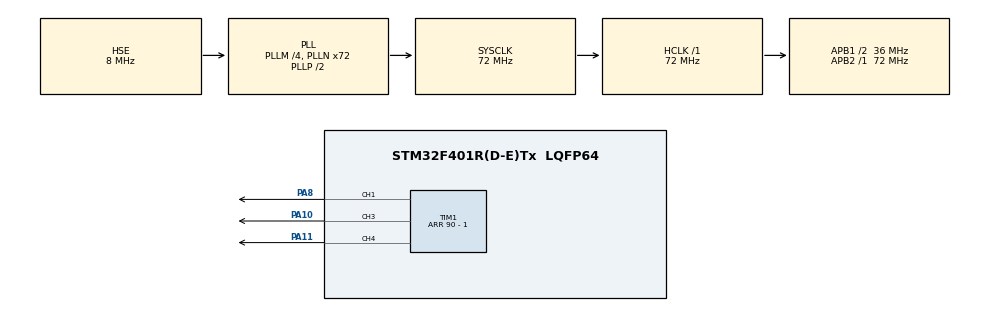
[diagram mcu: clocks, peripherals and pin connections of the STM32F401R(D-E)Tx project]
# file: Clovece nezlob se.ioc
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Dma.Request0=TIM1_CH1
Dma.Request1=TIM1_CH3
Dma.Request2=TIM1_CH4/TRIG/COM
Dma.TIM1_CH1.0.Direction=DMA_MEMORY_TO_PERIPH
Dma.TIM1_CH1.0.FIFOMode=DMA_FIFOMODE_DISABLE
Dma.TIM1_CH1.0.Instance=DMA2_Stream1
Dma.TIM1_CH1.0.MemDataAlignment=DMA_MDATAALIGN_HALFWORD
Dma.TIM1_CH1.0.MemInc=DMA_MINC_ENABLE
Dma.TIM1_CH1.0.Mode=DMA_NORMAL
Dma.TIM1_CH1.0.PeriphDataAlignment=DMA_PDATAALIGN_HALFWORD
Dma.TIM1_CH1.0.PeriphInc=DMA_PINC_DISABLE
Dma.TIM1_CH1.0.Priority=DMA_PRIORITY_LOW
Dma.TIM1_CH3.1.Direction=DMA_MEMORY_TO_PERIPH
Dma.TIM1_CH3.1.FIFOMode=DMA_FIFOMODE_DISABLE
Dma.TIM1_CH3.1.Instance=DMA2_Stream6
Dma.TIM1_CH3.1.MemDataAlignment=DMA_MDATAALIGN_HALFWORD
Dma.TIM1_CH3.1.MemInc=DMA_MINC_ENABLE
Dma.TIM1_CH3.1.Mode=DMA_NORMAL
Dma.TIM1_CH3.1.PeriphDataAlignment=DMA_PDATAALIGN_HALFWORD
Dma.TIM1_CH3.1.PeriphInc=DMA_PINC_DISABLE
Dma.TIM1_CH3.1.Priority=DMA_PRIORITY_LOW
Dma.TIM1_CH4/TRIG/COM.2.Direction=DMA_MEMORY_TO_PERIPH
Dma.TIM1_CH4/TRIG/COM.2.FIFOMode=DMA_FIFOMODE_DISABLE
Dma.TIM1_CH4/TRIG/COM.2.Instance=DMA2_Stream4
Dma.TIM1_CH4/TRIG/COM.2.MemDataAlignment=DMA_MDATAALIGN_HALFWORD
Dma.TIM1_CH4/TRIG/COM.2.MemInc=DMA_MINC_ENABLE
Dma.TIM1_CH4/TRIG/COM.2.Mode=DMA_NORMAL
Dma.TIM1_CH4/TRIG/COM.2.PeriphDataAlignment=DMA_PDATAALIGN_HALFWORD
Dma.TIM1_CH4/TRIG/COM.2.PeriphInc=DMA_PINC_DISABLE
Dma.TIM1_CH4/TRIG/COM.2.Priority=DMA_PRIORITY_LOW
Mcu.Family=STM32F4
Mcu.Name=STM32F401R(D-E)Tx
Mcu.Package=LQFP64
NVIC.DMA2_Stream1_IRQn=true\:0\:0\:false\:false\:true\:false\:true\:true
NVIC.DMA2_Stream4_IRQn=true\:0\:0\:false\:false\:true\:false\:true\:true
NVIC.DMA2_Stream6_IRQn=true\:0\:0\:false\:false\:true\:false\:true\:true
NVIC.PriorityGroup=NVIC_PRIORITYGROUP_4
PA10.Signal=S_TIM1_CH3
PA11.Signal=S_TIM1_CH4
PA8.Signal=S_TIM1_CH1
PH0\ -\ OSC_IN.Mode=HSE-External-Clock-Source
PH0\ -\ OSC_IN.Signal=RCC_OSC_IN
PH1\ -\ OSC_OUT.Mode=HSE-External-Clock-Source
PH1\ -\ OSC_OUT.Signal=RCC_OSC_OUT
ProjectManager.HeapSize=0x200
ProjectManager.StackSize=0x400
ProjectManager.TargetToolchain=STM32CubeIDE
RCC.48MHZClocksFreq_Value=36000000
RCC.AHBFreq_Value=72000000
RCC.APB1CLKDivider=RCC_HCLK_DIV2
RCC.APB1Freq_Value=36000000
RCC.APB1TimFreq_Value=72000000
RCC.APB2Freq_Value=72000000
RCC.APB2TimFreq_Value=72000000
RCC.CortexFreq_Value=72000000
RCC.HCLKFreq_Value=72000000
RCC.HSE_VALUE=8000000
RCC.HSI_VALUE=16000000
RCC.LSE_VALUE=32768
RCC.PLLM=4
RCC.PLLN=72
RCC.PLLSourceVirtual=RCC_PLLSOURCE_HSE
RCC.SYSCLKFreq_VALUE=72000000
RCC.SYSCLKSource=RCC_SYSCLKSOURCE_PLLCLK
RCC.VCOOutputFreq_Value=144000000
SH.S_TIM1_CH1.0=TIM1_CH1,PWM Generation1 CH1
SH.S_TIM1_CH3.0=TIM1_CH3,PWM Generation3 CH3
SH.S_TIM1_CH4.0=TIM1_CH4,PWM Generation4 CH4
TIM1.Channel-PWM\ Generation1\ CH1=TIM_CHANNEL_1
TIM1.Channel-PWM\ Generation3\ CH3=TIM_CHANNEL_3
TIM1.Channel-PWM\ Generation4\ CH4=TIM_CHANNEL_4
TIM1.Period=90 - 1
VP_TIM1_VS_ClockSourceINT.Mode=Internal
board=custom

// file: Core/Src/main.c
/* USER CODE BEGIN Header */
/**
  ******************************************************************************
  * @file           : main.c
  * @brief          : Main program body
  ******************************************************************************
  * @attention
  *
  * Copyright (c) 2024 STMicroelectronics.
  * All rights reserved.
  *
  * This software is licensed under terms that can be found in the LICENSE file
  * in the root directory of this software component.
  * If no LICENSE file comes with this software, it is provided AS-IS.
  *
  ******************************************************************************
  */
/* USER CODE END Header */
#include "main.h"

/* USER CODE BEGIN Includes */
#include "ws2812b.h"
#include "clovece_nezlob_se.h"
/* USER CODE END Includes */

TIM_HandleTypeDef htim1;
DMA_HandleTypeDef hdma_tim1_ch1;
DMA_HandleTypeDef hdma_tim1_ch3;
DMA_HandleTypeDef hdma_tim1_ch4_trig_com;

void SystemClock_Config(void);
static void MX_GPIO_Init(void);
static void MX_DMA_Init(void);
static void MX_TIM1_Init(void);

/* USER CODE BEGIN 0 */
void test_game(void);
void indivudual_bright(void);
/* USER CODE END 0 */

int main(void)
{

  /* MCU Configuration--------------------------------------------------------*/

  /* Reset of all peripherals, Initializes the Flash interface and the Systick. */
  HAL_Init();

  /* Conpawn the system clock */
  SystemClock_Config();

  /* Initialize all conpawnd peripherals */
  MX_GPIO_Init();
  MX_DMA_Init();
  MX_TIM1_Init();

  /* Infinite loop */
  /* USER CODE BEGIN WHILE */
  init_brightness();
  init_board(4);		//Bug - when more pawn of the same color are on the same postion and a pawn is meant to be kicked out all the pawns of the same color get kicked out instead of just one
  	  	  	  	  	  	//Add: animation effect when pawns of the same colora are oń the same position
  	  	  	  	  	  	//Add: cannot kickout when on the player x start postion, at the start of the game yiu can roll 3 times if you dont roll a 6
  // Test if all the pawns can reach the end
  /*
  for(int player = 1; player < 5; player++){
	  for(int pawn = 0; pawn < 4; pawn++){
		  select_pawn(player, pawn);
		  move_pawn(player, 6);
		  move_pawn(player, 50);
	  }
  }
  */
  test_game();

/*
  select_pawn(2, 0);
  move_pawn(2, 6);

  select_pawn(2, 1);
  move_pawn(2, 6);

  select_pawn(2, 2);
  move_pawn(2, 6);

  select_pawn(1, 0);
  move_pawn(1, 6);

  select_pawn(1, 1);
  move_pawn(1, 6);

  select_pawn(4, 0);
  move_pawn(4, 6);

  check_for_overlap();
  //roll_dice(1, 6);
  */
  check_for_overlap();

  while (1)
  {
	  overlap_animation();
	  selected_pawn_animation(4);
    /* USER CODE END WHILE */

  }
}

void SystemClock_Config(void)
{
  RCC_OscInitTypeDef RCC_OscInitStruct = {0};
  RCC_ClkInitTypeDef RCC_ClkInitStruct = {0};

  /** Conpawn the main internal regulator output voltage
  */
  __HAL_RCC_PWR_CLK_ENABLE();
  __HAL_PWR_VOLTAGESCALING_CONFIG(PWR_REGULATOR_VOLTAGE_SCALE2);

  /** Initializes the RCC Oscillators according to the specified parameters
  * in the RCC_OscInitTypeDef structure.
  */
  RCC_OscInitStruct.OscillatorType = RCC_OSCILLATORTYPE_HSE;
  RCC_OscInitStruct.HSEState = RCC_HSE_BYPASS;
  RCC_OscInitStruct.PLL.PLLState = RCC_PLL_ON;
  RCC_OscInitStruct.PLL.PLLSource = RCC_PLLSOURCE_HSE;
  RCC_OscInitStruct.PLL.PLLM = 4;
  RCC_OscInitStruct.PLL.PLLN = 72;
  RCC_OscInitStruct.PLL.PLLP = RCC_PLLP_DIV2;
  RCC_OscInitStruct.PLL.PLLQ = 4;
  if (HAL_RCC_OscConfig(&RCC_OscInitStruct) != HAL_OK)
  {
    Error_Handler();
  }

  /** Initializes the CPU, AHB and APB buses clocks
  */
  RCC_ClkInitStruct.ClockType = RCC_CLOCKTYPE_HCLK|RCC_CLOCKTYPE_SYSCLK
                              |RCC_CLOCKTYPE_PCLK1|RCC_CLOCKTYPE_PCLK2;
  RCC_ClkInitStruct.SYSCLKSource = RCC_SYSCLKSOURCE_PLLCLK;
  RCC_ClkInitStruct.AHBCLKDivider = RCC_SYSCLK_DIV1;
  RCC_ClkInitStruct.APB1CLKDivider = RCC_HCLK_DIV2;
  RCC_ClkInitStruct.APB2CLKDivider = RCC_HCLK_DIV1;

  if (HAL_RCC_ClockConfig(&RCC_ClkInitStruct, FLASH_LATENCY_2) != HAL_OK)
  {
    Error_Handler();
  }
}

static void MX_TIM1_Init(void)
{

  TIM_ClockConfigTypeDef sClockSourceConfig = {0};
  TIM_MasterConfigTypeDef sMasterConfig = {0};
  TIM_OC_InitTypeDef sConfigOC = {0};
  TIM_BreakDeadTimeConfigTypeDef sBreakDeadTimeConfig = {0};

  htim1.Instance = TIM1;
  htim1.Init.Prescaler = 0;
  htim1.Init.CounterMode = TIM_COUNTERMODE_UP;
  htim1.Init.Period = 90 - 1;
  htim1.Init.ClockDivision = TIM_CLOCKDIVISION_DIV1;
  htim1.Init.RepetitionCounter = 0;
  htim1.Init.AutoReloadPreload = TIM_AUTORELOAD_PRELOAD_DISABLE;
  if (HAL_TIM_Base_Init(&htim1) != HAL_OK)
  {
    Error_Handler();
  }
  sClockSourceConfig.ClockSource = TIM_CLOCKSOURCE_INTERNAL;
  if (HAL_TIM_ConfigClockSource(&htim1, &sClockSourceConfig) != HAL_OK)
  {
    Error_Handler();
  }
  if (HAL_TIM_PWM_Init(&htim1) != HAL_OK)
  {
    Error_Handler();
  }
  sMasterConfig.MasterOutputTrigger = TIM_TRGO_RESET;
  sMasterConfig.MasterSlaveMode = TIM_MASTERSLAVEMODE_DISABLE;
  if (HAL_TIMEx_MasterConfigSynchronization(&htim1, &sMasterConfig) != HAL_OK)
  {
    Error_Handler();
  }
  sConfigOC.OCMode = TIM_OCMODE_PWM1;
  sConfigOC.Pulse = 0;
  sConfigOC.OCPolarity = TIM_OCPOLARITY_HIGH;
  sConfigOC.OCNPolarity = TIM_OCNPOLARITY_HIGH;
  sConfigOC.OCFastMode = TIM_OCFAST_DISABLE;
  sConfigOC.OCIdleState = TIM_OCIDLESTATE_RESET;
  sConfigOC.OCNIdleState = TIM_OCNIDLESTATE_RESET;
  if (HAL_TIM_PWM_ConfigChannel(&htim1, &sConfigOC, TIM_CHANNEL_1) != HAL_OK)
  {
    Error_Handler();
  }
  if (HAL_TIM_PWM_ConfigChannel(&htim1, &sConfigOC, TIM_CHANNEL_3) != HAL_OK)
  {
    Error_Handler();
  }
  if (HAL_TIM_PWM_ConfigChannel(&htim1, &sConfigOC, TIM_CHANNEL_4) != HAL_OK)
  {
    Error_Handler();
  }
  sBreakDeadTimeConfig.OffStateRunMode = TIM_OSSR_DISABLE;
  sBreakDeadTimeConfig.OffStateIDLEMode = TIM_OSSI_DISABLE;
  sBreakDeadTimeConfig.LockLevel = TIM_LOCKLEVEL_OFF;
  sBreakDeadTimeConfig.DeadTime = 0;
  sBreakDeadTimeConfig.BreakState = TIM_BREAK_DISABLE;
  sBreakDeadTimeConfig.BreakPolarity = TIM_BREAKPOLARITY_HIGH;
  sBreakDeadTimeConfig.AutomaticOutput = TIM_AUTOMATICOUTPUT_DISABLE;
  if (HAL_TIMEx_ConfigBreakDeadTime(&htim1, &sBreakDeadTimeConfig) != HAL_OK)
  {
    Error_Handler();
  }
  HAL_TIM_MspPostInit(&htim1);

}

static void MX_DMA_Init(void)
{

  /* DMA controller clock enable */
  __HAL_RCC_DMA2_CLK_ENABLE();

  /* DMA interrupt init */
  /* DMA2_Stream1_IRQn interrupt configuration */
  HAL_NVIC_SetPriority(DMA2_Stream1_IRQn, 0, 0);
  HAL_NVIC_EnableIRQ(DMA2_Stream1_IRQn);
  /* DMA2_Stream4_IRQn interrupt configuration */
  HAL_NVIC_SetPriority(DMA2_Stream4_IRQn, 0, 0);
  HAL_NVIC_EnableIRQ(DMA2_Stream4_IRQn);
  /* DMA2_Stream6_IRQn interrupt configuration */
  HAL_NVIC_SetPriority(DMA2_Stream6_IRQn, 0, 0);
  HAL_NVIC_EnableIRQ(DMA2_Stream6_IRQn);

}

static void MX_GPIO_Init(void)
{

  /* GPIO Ports Clock Enable */
  __HAL_RCC_GPIOH_CLK_ENABLE();
  __HAL_RCC_GPIOA_CLK_ENABLE();

}

/* USER CODE BEGIN 4 */
void test_game(void){
	  select_pawn(2, 1);
	  move_pawn(2, 6);

	  select_pawn(2, 3);
	  move_pawn(2, 6);

	  select_pawn(2, 2);
	  move_pawn(2, 6);

	  select_pawn(2, 0);
	  move_pawn(2, 6);

	  //move pawn from player 4
	  select_pawn(4, 0);
	  move_pawn(4, 6);

	  //move pawn on the board
	  select_pawn(2, 2);
	  move_pawn(2, 3);

	  select_pawn(2, 1);
	  move_pawn(2, 5);

	  select_pawn(2, 3);
	  move_pawn(2, 6);

	  select_pawn(2, 0);
	  move_pawn(2, 2);

	  select_pawn(4, 0);
	  move_pawn(4, 2);

	  // Sets the pawn to the start of the board
	  move_pawn(2, 40);

	  select_pawn(2, 1);
	  move_pawn(2, 40);

	  select_pawn(2, 2);
	  move_pawn(2, 40);

	  select_pawn(2, 3);
	  move_pawn(2, 40);

	  select_pawn(1, 2);
	  move_pawn(1, 2);

	  move_pawn(1, 6);
	  move_pawn(1, 40);

	  select_pawn(1, 3);
	  move_pawn(1, 6);
	  move_pawn(1, 6);

	  select_pawn(3, 3);
	  move_pawn(3, 6);
	  move_pawn(3, 40);

	  select_pawn(4, 0);
	  move_pawn(4, 6);
	  move_pawn(4, 40);

}

void indivudual_bright(void){

	for(int i = 0; i < NUM_OF_LEDS_START; i++){
		set_LED_color(i, START, 229, 83, 0);
		set_brightness_individually(i, START, i + 50);
		send_data(START);
		HAL_Delay(200);
	}
}
/* USER CODE END 4 */

void Error_Handler(void)
{
  __disable_irq();
  while (1)
  {
  }
}
